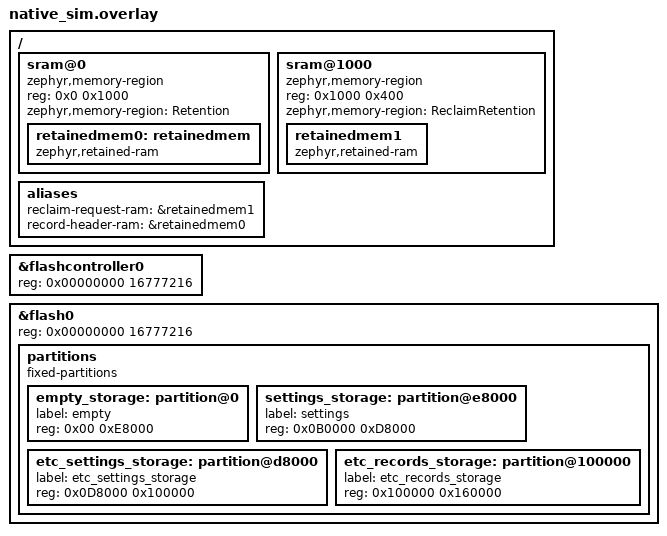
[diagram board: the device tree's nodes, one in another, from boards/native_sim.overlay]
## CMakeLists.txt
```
cmake_minimum_required(VERSION 3.20.0)
find_package(Zephyr REQUIRED HINTS $ENV{ZEPHYR_BASE})
project(etc_always_on)

FILE(GLOB app_sources src/*.c
                      src/mock/*.c
                      src/mock/cloud/cloud_codec/lwm2m/lwm2m_codec.c
                      src/mock/zephyr/drivers/*.c)
                      
set(APP_SRC_DIR ../../../../applications/etc-app/src)

target_compile_options(app PRIVATE -Wno-error=double-promotion)

target_include_directories(app PRIVATE
                            src
                            src/mock 
                            src/mock/cloud/cloud_codec
                            src/mock/zephyr/drivers
                            ${APP_SRC_DIR}/exact/etc_devices
                            ${APP_SRC_DIR}/exact/etc_memfault
                            ${APP_SRC_DIR}/exact/etc_settings
                            ${APP_SRC_DIR}/exact/etc_sensor
                            ${APP_SRC_DIR}/exact/etc_util
                            ${APP_SRC_DIR}/exact/etc_calibration
                            ${APP_SRC_DIR})

target_sources(app PRIVATE ${app_sources}
                ${APP_SRC_DIR}/exact/etc_devices/etc_device.c
                ${APP_SRC_DIR}/exact/etc_devices/etc_device_record.c
                ${APP_SRC_DIR}/exact/etc_settings/etc_settings.c
                ${APP_SRC_DIR}/exact/etc_memfault/etc_memfault_dummy.c
                ${APP_SRC_DIR}/exact/etc_util/etc_util.c
)
 
zephyr_compile_definitions_ifdef(CONFIG_BOARD_NATIVE_SIM CONFIG_BOARD_VERSION="0.0.0")
zephyr_compile_definitions(CONFIG_LWM2M_SECURITY_KEY_SIZE=33)
zephyr_compile_definitions(CONFIG_SERIAL_NUMBER_TYPE=1)
zephyr_compile_definitions(CONFIG_SERIAL_NUMBER_DEFAULT_VALUE=10000000)
zephyr_compile_definitions(CONFIG_LWM2M_INTEGRATION_PSK="70475440693636213646256D7744")
zephyr_compile_definitions(CONFIG_MODEM_MODULE_GNSS_TIMEOUT_S=60)
zephyr_compile_definitions(CONFIG_ETC_APP_THRESHOLD_MIN_REPORT_INTERVAL_S=900)
zephyr_compile_definitions(CONFIG_MODEM_MODULE_MAX_CONNECTION_TIME_S=60)
zephyr_compile_definitions(IMAGE_HASH_LEN=32)
zephyr_compile_definitions(CONFIG_ETC_APP_LOG_LEVEL=3)
zephyr_compile_definitions(CONFIG_ETC_SETTINGS_LOG_LEVEL=3)
zephyr_compile_definitions(CONFIG_ETC_DEVICE_RELAY_MAX_RECORD_HISTORY=64)
zephyr_compile_definitions(CONFIG_ETC_DEVICE_SAVE_RECORD_SEC=1)
```

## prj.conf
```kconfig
CONFIG_ZTEST=y
CONFIG_HEAP_MEM_POOL_SIZE=8192
CONFIG_RETAINED_MEM=y

CONFIG_FLASH=y
CONFIG_FLASH_PAGE_LAYOUT=y
CONFIG_FLASH_MAP=y
CONFIG_NVS=y

# Settings - Used to store real-time device configuration to flash.
CONFIG_SETTINGS=y
CONFIG_SETTINGS_FCB=y
CONFIG_FCB=y

CONFIG_POSIX_API=y

# Application Event Manager
CONFIG_APP_EVENT_MANAGER=y
CONFIG_APP_EVENT_MANAGER_LOG_EVENT_TYPE=n

CONFIG_TEST_RANDOM_GENERATOR=y
```

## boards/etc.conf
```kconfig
# Flash
CONFIG_SOC_FLASH_NRF_UICR=y
CONFIG_MPU_ALLOW_FLASH_WRITE=y

# Partition Manager
CONFIG_PM_SINGLE_IMAGE=y
CONFIG_PM_OVERRIDE_EXTERNAL_DRIVER_CHECK=y
CONFIG_PM_PARTITION_REGION_SETTINGS_STORAGE_EXTERNAL=n
CONFIG_PM_PARTITION_REGION_NVS_STORAGE_EXTERNAL=y

# segger RTT console
CONFIG_LOG_MODE_DEFERRED=y
CONFIG_USE_SEGGER_RTT=y
CONFIG_RTT_CONSOLE=n
CONFIG_LOG_BACKEND_RTT=y
CONFIG_LOG_MODE_MINIMAL=n
CONFIG_SHELL_LOG_BACKEND=n
CONFIG_SHELL_BACKEND_SERIAL=y

# Disable not needed devices
CONFIG_SHELL_BACKEND_SERIAL=n
CONFIG_CONSOLE=n
CONFIG_UART_CONSOLE=n
```

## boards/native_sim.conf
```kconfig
CONFIG_FLASH_SIMULATOR=y

CONFIG_RETAINED_MEM_ZEPHYR_RAM=n
CONFIG_RETAINED_MEM_MOCK_RAM=y
```

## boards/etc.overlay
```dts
/ {
	sram@2003F000 {
		compatible = "zephyr,memory-region", "mmio-sram";
		reg = <0x2003F000 0x1000>;
		zephyr,memory-region = "RetainedMem";
		status = "okay";

		retainedmem0: retainedmem {
			compatible = "zephyr,retained-ram";
			status = "okay";
	        };
        };

	aliases {
		record-header-ram = &retainedmem0;
	};
};
```

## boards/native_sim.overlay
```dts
/ {
	sram@0 {
		compatible = "zephyr,memory-region";
		reg = <0x0 0x1000>;
		status = "okay";
		zephyr,memory-region = "Retention";

		retainedmem0: retainedmem {
			compatible = "zephyr,retained-ram";
			status = "okay";
		};
	};
	sram@1000 {
		compatible = "zephyr,memory-region";
		reg = <0x1000 0x400>;
		status = "okay";
		zephyr,memory-region = "ReclaimRetention";

		retainedmem1: retainedmem1 {
			compatible = "zephyr,retained-ram";
			status = "okay";
		};
	};

	aliases {
		reclaim-request-ram = &retainedmem1;
		record-header-ram = &retainedmem0;
	};
};

&flashcontroller0 {
	reg = <0x00000000 16777216>;
};

&flash0 {
	reg = <0x00000000 16777216>;

	partitions {
		compatible = "fixed-partitions";
		#address-cells = <1>;
		#size-cells = <1>;

		/delete-node/ boot_partition;
		/delete-node/ slot0_partition;
		/delete-node/ slot1_partition;
		/delete-node/ scratch_partition;
		/delete-node/ storage_partition;

		empty_storage: partition@0 {
			label = "empty";
			reg = < 0x00 0xE8000 >;
		};
		settings_storage: partition@e8000 {
			label = "settings";
			reg = < 0x0B0000 0xD8000 >;
		};
		etc_settings_storage: partition@d8000 {
			label = "etc_settings_storage";
			reg = < 0x0D8000 0x100000 >;
		};
		etc_records_storage: partition@100000 {
			label = "etc_records_storage";
			reg = < 0x100000 0x160000 >;
		};
	};
};
```

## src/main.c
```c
/*
 * Copyright (c) 2024 EXACT Technology Corporation
 */

#include <stdbool.h>
#include <string.h>
#include <zephyr/ztest.h>

#include "etc_device.h"
#include "etc_device_record.h"
#include "etc_settings.h"
#include "etc_util.h"
#include <zephyr/logging/log.h>
#include <zephyr/random/random.h>

LOG_MODULE_REGISTER(etc_always_on, CONFIG_ETC_APP_LOG_LEVEL);

static void *test_setup(void)
{
	etc_settings_init();
	return NULL;
}

ZTEST(etc_always_on_test, test_01_on_boot_up)
{
	zassert_equal(etc_get_device_mode(), ETC_SETTING_DEVICE_MODE_DEFAULT);
	zassert_equal(etc_get_power_mode(), ETC_SETTING_POWER_MODE_DEFAULT);
}

ZTEST(etc_always_on_test, test_02_on_not_relay_mode)
{
	enum etc_power_mode_e previous_power_mode = etc_get_power_mode();
	/* Not Relay Mode */
	zassert_not_equal(etc_get_device_mode(), ETC_DEVICE_MODE_RELAY);
	etc_set_power_mode(ETC_POWER_MODE_ALWAYS_ON);
	zassert_equal(previous_power_mode, etc_get_power_mode());
}

ZTEST(etc_always_on_test, test_03_on_relay_mode)
{
	/* Set Relay Mode */
	etc_set_device_mode(ETC_DEVICE_MODE_RELAY);
	etc_set_power_mode(ETC_POWER_MODE_ALWAYS_ON);
	zassert_equal(etc_get_power_mode(), ETC_POWER_MODE_ALWAYS_ON);
}

ZTEST(etc_always_on_test, test_04_on_change_mode)
{
	/* Set Relay Mode & Power mode*/
	etc_set_device_mode(ETC_DEVICE_MODE_RELAY);
	etc_set_power_mode(ETC_POWER_MODE_ALWAYS_ON);
	zassert_equal(etc_get_power_mode(), ETC_POWER_MODE_ALWAYS_ON);
	etc_set_power_mode(ETC_POWER_MODE_INTERVAL);
	zassert_equal(etc_get_power_mode(), ETC_POWER_MODE_INTERVAL);
}

ZTEST(etc_always_on_test, test_05_on_switch_mode)
{
	/* Set Relay Mode & Power mode*/
	etc_set_device_mode(ETC_DEVICE_MODE_RELAY);
	etc_set_power_mode(ETC_POWER_MODE_ALWAYS_ON);
	zassert_equal(etc_get_power_mode(), ETC_POWER_MODE_ALWAYS_ON);
	etc_set_device_mode(ETC_DEVICE_MODE_LTE_LOGGER);
	zassert_equal(etc_get_power_mode(), ETC_POWER_MODE_INTERVAL);
}

#if CONFIG_BOARD_ETC
ZTEST(etc_always_on_test, test_06_lora_rx_active)
{
	zassert_equal(etc_get_power_mode(), ETC_POWER_MODE_INTERVAL);
}
#endif

ZTEST_SUITE(etc_always_on_test, NULL, test_setup, NULL, NULL, NULL);
```

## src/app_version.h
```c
/**
 * @file app_version.h
 *
 * Application version information.
 *
 * Copyright (c) 2021 Nordic Semiconductor ASA
 * SPDX-License-Identifier: Apache-2.0
 */

#ifndef APP_VERSION_H_
#define APP_VERSION_H_

/** Application major version. */
#define APP_VERSION_MAJOR 1
/** Application minor version. */
#define APP_VERSION_MINOR 2
/** Application patch version. */
#define APP_VERSION_PATCH 2

/** Application version. */
#define APP_VERSION \
	((APP_VERSION_MAJOR << 16) + \
	 (APP_VERSION_MINOR << 8) + \
	  APP_VERSION_PATCH)

/** Application version (string). */
#define APP_VERSION_STRING "1.2.2-rc1"

/** Numerical Application version string (MAJOR.MINOR.PATCH) without suffix (e.g. -rc) */
#define APP_VERSION_NUM_STR "1.2.2"

#endif /* APP_VERSION_H_ */
```

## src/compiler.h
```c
#ifndef _APP_COMPILER_H_
#define _APP_COMPILER_H_

#pragma GCC diagnostic ignored "-Wunused-function"
#pragma GCC diagnostic ignored "-Wunused-variable"

#endif /* _APP_COMPILER_H_ */
```
